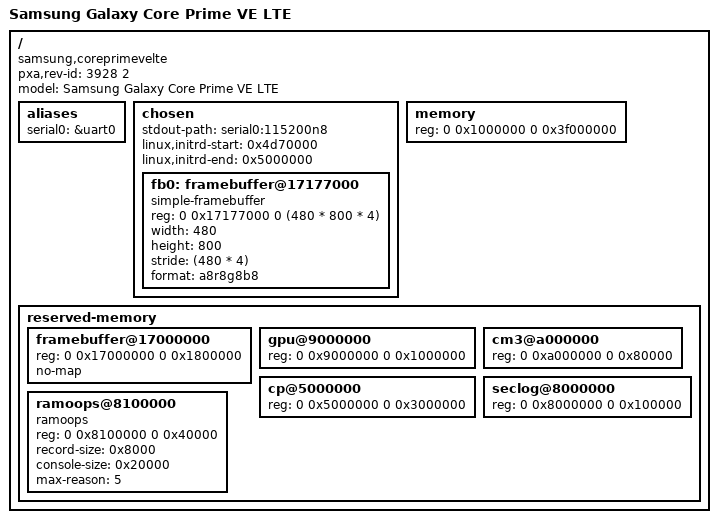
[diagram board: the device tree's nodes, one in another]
// SPDX-License-Identifier: GPL-2.0-only
#include "pxa1908.dtsi"

/ {
	pxa,rev-id = <3928 2>;
	model = "Samsung Galaxy Core Prime VE LTE";
	compatible = "samsung,coreprimevelte", "marvell,pxa1908";

	aliases {
		serial0 = &uart0;
	};

	chosen {
		#address-cells = <2>;
		#size-cells = <2>;
		ranges;

		stdout-path = "serial0:115200n8";

		/* S-Boot places the initramfs here */
		linux,initrd-start = <0x4d70000>;
		linux,initrd-end = <0x5000000>;

		fb0: framebuffer@17177000 {
			compatible = "simple-framebuffer";
			reg = <0 0x17177000 0 (480 * 800 * 4)>;
			width = <480>;
			height = <800>;
			stride = <(480 * 4)>;
			format = "a8r8g8b8";
		};
	};

	memory {
		device_type = "memory";
		reg = <0 0x1000000 0 0x3f000000>;
	};

	reserved-memory {
		#address-cells = <2>;
		#size-cells = <2>;
		ranges;

		framebuffer@17000000 {
			reg = <0 0x17000000 0 0x1800000>;
			no-map;
		};

		gpu@9000000 {
			reg = <0 0x9000000 0 0x1000000>;
		};

		/* Communications processor, aka modem */
		cp@5000000 {
			reg = <0 0x5000000 0 0x3000000>;
		};

		cm3@a000000 {
			reg = <0 0xa000000 0 0x80000>;
		};

		seclog@8000000 {
			reg = <0 0x8000000 0 0x100000>;
		};

		ramoops@8100000 {
			compatible = "ramoops";
			reg = <0 0x8100000 0 0x40000>;
			record-size = <0x8000>;
			console-size = <0x20000>;
			max-reason = <5>;
		};
	};
};
